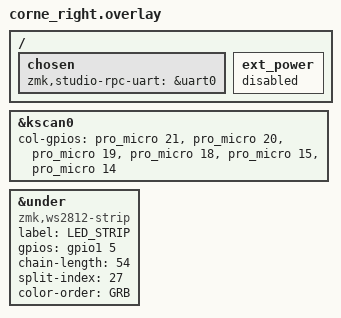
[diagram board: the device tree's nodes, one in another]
#include "corne.dtsi"

&kscan0 {
    col-gpios =
        <&pro_micro 21 GPIO_ACTIVE_HIGH>,
        <&pro_micro 20 GPIO_ACTIVE_HIGH>,
        <&pro_micro 19 GPIO_ACTIVE_HIGH>,
        <&pro_micro 18 GPIO_ACTIVE_HIGH>,
        <&pro_micro 15 GPIO_ACTIVE_HIGH>,
        <&pro_micro 14 GPIO_ACTIVE_HIGH>;
};

&under {
    compatible = "zmk,ws2812-strip";
    label = "LED_STRIP";
    gpios = <&gpio1 5 GPIO_ACTIVE_HIGH>; // dùng đúng chân bạn đang hàn
    chain-length = <54>;       // Tổng số LED trên cả 2 bên: 27 mỗi bên
    split-index = <27>;        // LED bên trái = 27, bên phải cũng phải khai báo vậy để đồng bộ
    color-order = <GRB>;       // Thử lại RGB nếu màu bị sai
    status = "okay";
};

/ {
    chosen {
        zmk,studio-rpc-uart = &uart0;
    };
};


/ {
    ext_power {
        status = "disabled";
    };
};
